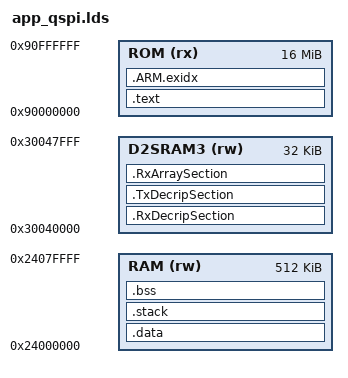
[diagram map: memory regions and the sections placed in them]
/*
 * Linker script for the RT-Thread application executed from W25Q128 QSPI flash.
 */

MEMORY
{
    ROM (rx) : ORIGIN = 0x90000000, LENGTH = 16M
    RAM (rw) : ORIGIN = 0x24000000, LENGTH = 512k
    D2SRAM3 (rw) : ORIGIN = 0x30040000, LENGTH = 32k
}
ENTRY(Reset_Handler)
_system_stack_size = 0x400;

SECTIONS
{
    .text :
    {
        . = ALIGN(4);
        _stext = .;
        KEEP(*(.isr_vector))

        . = ALIGN(4);
        *(.text)
        *(.text.*)
        *(.rodata)
        *(.rodata*)
        *(.glue_7)
        *(.glue_7t)
        *(.gnu.linkonce.t*)

        . = ALIGN(4);
        __fsymtab_start = .;
        KEEP(*(FSymTab))
        __fsymtab_end = .;

        . = ALIGN(4);
        __vsymtab_start = .;
        KEEP(*(VSymTab))
        __vsymtab_end = .;

        . = ALIGN(4);
        __rt_utest_tc_tab_start = .;
        KEEP(*(UtestTcTab))
        __rt_utest_tc_tab_end = .;

        . = ALIGN(4);
        __rtatcmdtab_start = .;
        KEEP(*(RtAtCmdTab))
        __rtatcmdtab_end = .;
        . = ALIGN(4);

        . = ALIGN(4);
        __rt_init_start = .;
        KEEP(*(SORT(.rti_fn*)))
        __rt_init_end = .;

        . = ALIGN(4);

        PROVIDE(__ctors_start__ = .);
        KEEP (*(SORT(.init_array.*)))
        KEEP (*(.init_array))
        PROVIDE(__ctors_end__ = .);

        . = ALIGN(4);

        _etext = .;
    } > ROM = 0

    __exidx_start = .;
    .ARM.exidx :
    {
        *(.ARM.exidx* .gnu.linkonce.armexidx.*)
        _sidata = .;
    } > ROM
    __exidx_end = .;

    .data : AT (_sidata)
    {
        . = ALIGN(4);
        _sdata = . ;

        *(.data)
        *(.data.*)
        *(.gnu.linkonce.d*)

        PROVIDE(__dtors_start__ = .);
        KEEP(*(SORT(.dtors.*)))
        KEEP(*(.dtors))
        PROVIDE(__dtors_end__ = .);

        . = ALIGN(4);
        _edata = . ;
    } >RAM

    .stack :
    {
        . = ALIGN(8);
        _sstack = .;
        . = . + _system_stack_size;
        . = ALIGN(8);
        _estack = .;
    } >RAM

    __bss_start = .;
    .bss :
    {
        . = ALIGN(4);
        _sbss = .;

        *(.bss)
        *(.bss.*)
        *(COMMON)

        . = ALIGN(4);
        _ebss = . ;

        *(.bss.init)
    } > RAM
    __bss_end = .;

    _end = .;

    .RxDecripSection (NOLOAD) :
    {
        . = ALIGN(32);
        KEEP(*(.RxDecripSection))
    } > D2SRAM3

    .TxDecripSection (NOLOAD) :
    {
        . = ALIGN(32);
        KEEP(*(.TxDecripSection))
    } > D2SRAM3

    .RxArraySection (NOLOAD) :
    {
        . = ALIGN(32);
        KEEP(*(.RxArraySection))
    } > D2SRAM3

    .stab          0 : { *(.stab) }
    .stabstr       0 : { *(.stabstr) }
    .stab.excl     0 : { *(.stab.excl) }
    .stab.exclstr  0 : { *(.stab.exclstr) }
    .stab.index    0 : { *(.stab.index) }
    .stab.indexstr 0 : { *(.stab.indexstr) }
    .comment       0 : { *(.comment) }
    .debug          0 : { *(.debug) }
    .line           0 : { *(.line) }
    .debug_srcinfo  0 : { *(.debug_srcinfo) }
    .debug_sfnames  0 : { *(.debug_sfnames) }
    .debug_aranges  0 : { *(.debug_aranges) }
    .debug_pubnames 0 : { *(.debug_pubnames) }
    .debug_info     0 : { *(.debug_info .gnu.linkonce.wi.*) }
    .debug_abbrev   0 : { *(.debug_abbrev) }
    .debug_line     0 : { *(.debug_line) }
    .debug_frame    0 : { *(.debug_frame) }
    .debug_str      0 : { *(.debug_str) }
    .debug_loc      0 : { *(.debug_loc) }
    .debug_macinfo  0 : { *(.debug_macinfo) }
    .debug_weaknames 0 : { *(.debug_weaknames) }
    .debug_funcnames 0 : { *(.debug_funcnames) }
    .debug_typenames 0 : { *(.debug_typenames) }
    .debug_varnames  0 : { *(.debug_varnames) }
}
